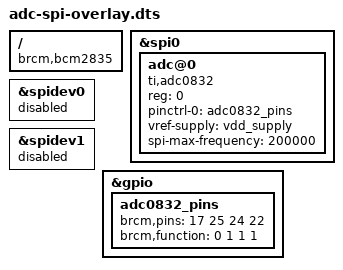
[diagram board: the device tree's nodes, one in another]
/*
 * Device Tree overlay for PiScreen 3.5" display shield by Ozzmaker
 *
 */

/dts-v1/;
/plugin/;

/ {
	compatible = "brcm,bcm2835\0brcm,bcm2835\0brcm,bcm2708\0brcm,bcm2709";

	fragment@0 {
		target = <&spi0>;
		__overlay__ {
			status = "okay";
		};
	};

	fragment@1 {
		target = <&spidev0>;
		__overlay__ {
			status = "disabled";
		};
	};

	fragment@2 {
		target = <&spidev1>;
		__overlay__ {
			status = "disabled";
		};
	};

	fragment@3 {
		target = <&gpio>;
		__overlay__ {
			adc0832_pins: adc0832_pins {
				brcm,pins = <17 25 24 22>;
				brcm,function = <0 1 1 1>; /* in out out out */
			};
		};
	};

	fragment@4 {
		target = <&spi0>;
		__overlay__ {
			/* needed to avoid dtc warning */
			#address-cells = <1>;
			#size-cells = <0>;

        adc@0 {
            compatible = "ti,adc0832";
            reg = <0>;
			pinctrl-names = "default";
			pinctrl-0 = <&adc0832_pins>;
            vref-supply = <&vdd_supply>;
            spi-max-frequency = <200000>;
		};
	};
};
	__overrides__ {
	};
};
